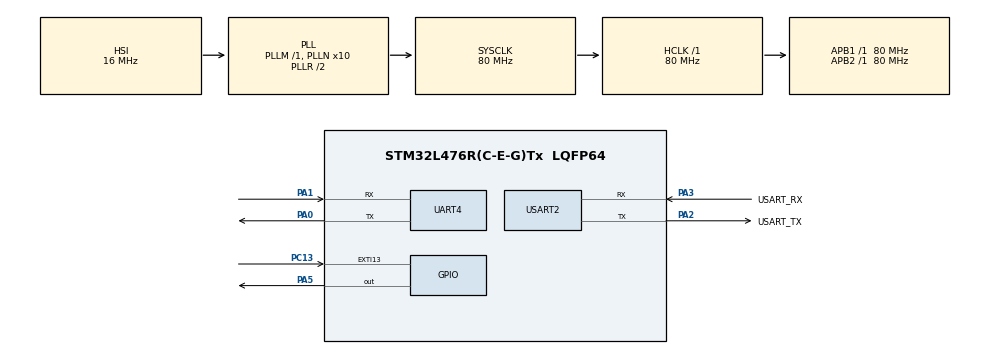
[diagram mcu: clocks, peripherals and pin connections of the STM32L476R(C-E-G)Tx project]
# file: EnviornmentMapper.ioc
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Mcu.Family=STM32L4
Mcu.Name=STM32L476R(C-E-G)Tx
Mcu.Package=LQFP64
NUCLEO-L476RG.BUTTON=1
NUCLEO-L476RG.LD2=true
NVIC.EXTI15_10_IRQn=true\:0\:0\:false\:false\:true\:false\:true\:true
NVIC.PriorityGroup=NVIC_PRIORITYGROUP_4
PA0.Mode=Asynchronous
PA0.Signal=UART4_TX
PA1.Mode=Asynchronous
PA1.Signal=UART4_RX
PA13\ (JTMS-SWDIO).GPIO_Label=TMS
PA13\ (JTMS-SWDIO).Signal=SYS_JTMS-SWDIO
PA14\ (JTCK-SWCLK).GPIO_Label=TCK
PA14\ (JTCK-SWCLK).Signal=SYS_JTCK-SWCLK
PA2.GPIO_Label=USART_TX
PA2.GPIO_Mode=GPIO_MODE_AF_PP
PA2.GPIO_PuPd=GPIO_NOPULL
PA2.GPIO_Speed=GPIO_SPEED_FREQ_VERY_HIGH
PA2.Mode=Asynchronous
PA2.Signal=USART2_TX
PA3.GPIO_Label=USART_RX
PA3.GPIO_Mode=GPIO_MODE_AF_PP
PA3.GPIO_PuPd=GPIO_NOPULL
PA3.GPIO_Speed=GPIO_SPEED_FREQ_VERY_HIGH
PA3.Mode=Asynchronous
PA3.Signal=USART2_RX
PA5.Signal=GPIO_Output
PB3\ (JTDO-TRACESWO).GPIO_Label=SWO
PB3\ (JTDO-TRACESWO).Signal=SYS_JTDO-SWO
PC13.Signal=GPXTI13
PC14-OSC32_IN\ (PC14).Signal=RCC_OSC32_IN
PC15-OSC32_OUT\ (PC15).Signal=RCC_OSC32_OUT
PH0-OSC_IN\ (PH0).Signal=RCC_OSC_IN
PH1-OSC_OUT\ (PH1).Signal=RCC_OSC_OUT
ProjectManager.HeapSize=0x200
ProjectManager.StackSize=0x400
ProjectManager.TargetToolchain=STM32CubeIDE
RCC.ADCFreq_Value=64000000
RCC.AHBFreq_Value=80000000
RCC.APB1Freq_Value=80000000
RCC.APB1TimFreq_Value=80000000
RCC.APB2Freq_Value=80000000
RCC.APB2TimFreq_Value=80000000
RCC.CortexFreq_Value=80000000
RCC.HCLKFreq_Value=80000000
RCC.HSE_VALUE=8000000
RCC.HSI_VALUE=16000000
RCC.LSE_VALUE=32768
RCC.MSI_VALUE=4000000
RCC.PLLN=10
RCC.PLLSourceVirtual=RCC_PLLSOURCE_HSI
RCC.PREFETCH_ENABLE=1
RCC.SYSCLKFreq_VALUE=80000000
RCC.SYSCLKSource=RCC_SYSCLKSOURCE_PLLCLK
RCC.USBFreq_Value=64000000
RCC.VCOOutputFreq_Value=160000000
USART2.VirtualMode-Asynchronous=VM_ASYNC
VP_NUCLEO-L476RG_VS_BSP_COMMON.Mode=COMMON
board=NUCLEO-L476RG

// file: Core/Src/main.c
/* USER CODE BEGIN Header */
/**
  ******************************************************************************
  * @file           : main.c
  * @brief          : Main program body
  ******************************************************************************
  * @attention
  *
  * Copyright (c) 2026 STMicroelectronics.
  * All rights reserved.
  *
  * This software is licensed under terms that can be found in the LICENSE file
  * in the root directory of this software component.
  * If no LICENSE file comes with this software, it is provided AS-IS.
  *
  ******************************************************************************
  */
/* USER CODE END Header */
#include "main.h"
#include "stdio.h"

UART_HandleTypeDef huart4;
UART_HandleTypeDef huart2;

/* USER CODE BEGIN PV */
// Buffer for UART transmission/reception

uint8_t obuffer[8]; // onput buffer (this really is the input buffer, but I didn't want to change it since obuffer looks cooler than ibuffer)
int pan_amt;
int tilt_amt;
int distance;

/* USER CODE END PV */

void SystemClock_Config(void);
static void MX_GPIO_Init(void);
static void MX_UART4_Init(void);
static void MX_USART2_UART_Init(void);
/* USER CODE BEGIN PFP */
#define PUTCHAR_PROTOTYPE int __io_putchar(int ch)
/* USER CODE END PFP */

int main(void)
{

  /* MCU Configuration--------------------------------------------------------*/

  /* Reset of all peripherals, Initializes the Flash interface and the Systick. */
  HAL_Init();

  /* Configure the system clock */
  SystemClock_Config();

  /* Initialize all configured peripherals */
  MX_GPIO_Init();
  MX_UART4_Init();
  MX_USART2_UART_Init();

  /* Initialize leds */
  BSP_LED_Init(LED_GREEN);

  /* Initialize USER push-button, will be used to trigger an interrupt each time it's pressed.*/
  BSP_PB_Init(BUTTON_USER, BUTTON_MODE_EXTI);

  /* Infinite loop */
  /* USER CODE BEGIN WHILE */
  while (1)
  {
	pan_amt = 0;
	tilt_amt = 0;
	// Receive data, 0x56, 0x56, distance, distance
	// Which is essentially a state machine
	// Which is irrelevant to the actual program, just the more you know
	/*while (1) {
		HAL_UART_Receive(&huart4, obuffer, 1, 0xFFFF); // State 0
		if (obuffer[0] == 59) { // Cortex M4 does not have speculative execution so this isn't terrible
			// Do it again
			HAL_UART_Receive(&huart4, obuffer, 1, 0xFFFF); // State 1
			if (obuffer[0] == 59) { // Cortex M4 does not have speculative execution so this isn't terrible
						// Now we actually recieve the data
						HAL_UART_Receive(&huart4, obuffer, 1, 0xFFFF);
						distance = obuffer[0];
						HAL_UART_Receive(&huart4, obuffer, 1, 0xFFFF);
						distance = obuffer[0];
						break; // Break from loop to transmit data
					}
		}
	}*/
	// Recieve From UART4 (Pin A1), this only recieves the first bit for some reason,
	// meaning we need to increase the 'obuffer'
	HAL_UART_Receive(&huart4, obuffer, 8, 0xFFFF);
	// Transmit with newline
	// printf("%d%d%d\n\r", pan_amt, tilt_amt, distance);
	printf("%x-%x-%x-%x-%x-%x-%x-%x\n\r", obuffer[0], obuffer[1], obuffer[2], obuffer[3], obuffer[4], obuffer[5], obuffer[6], obuffer[7]);
	// Delay
	HAL_Delay(1000);

    /* USER CODE END WHILE */

  }
}

void SystemClock_Config(void)
{
  RCC_OscInitTypeDef RCC_OscInitStruct = {0};
  RCC_ClkInitTypeDef RCC_ClkInitStruct = {0};

  /** Configure the main internal regulator output voltage
  */
  if (HAL_PWREx_ControlVoltageScaling(PWR_REGULATOR_VOLTAGE_SCALE1) != HAL_OK)
  {
    Error_Handler();
  }

  /** Initializes the RCC Oscillators according to the specified parameters
  * in the RCC_OscInitTypeDef structure.
  */
  RCC_OscInitStruct.OscillatorType = RCC_OSCILLATORTYPE_HSI;
  RCC_OscInitStruct.HSIState = RCC_HSI_ON;
  RCC_OscInitStruct.HSICalibrationValue = RCC_HSICALIBRATION_DEFAULT;
  RCC_OscInitStruct.PLL.PLLState = RCC_PLL_ON;
  RCC_OscInitStruct.PLL.PLLSource = RCC_PLLSOURCE_HSI;
  RCC_OscInitStruct.PLL.PLLM = 1;
  RCC_OscInitStruct.PLL.PLLN = 10;
  RCC_OscInitStruct.PLL.PLLP = RCC_PLLP_DIV7;
  RCC_OscInitStruct.PLL.PLLQ = RCC_PLLQ_DIV2;
  RCC_OscInitStruct.PLL.PLLR = RCC_PLLR_DIV2;
  if (HAL_RCC_OscConfig(&RCC_OscInitStruct) != HAL_OK)
  {
    Error_Handler();
  }

  /** Initializes the CPU, AHB and APB buses clocks
  */
  RCC_ClkInitStruct.ClockType = RCC_CLOCKTYPE_HCLK|RCC_CLOCKTYPE_SYSCLK
                              |RCC_CLOCKTYPE_PCLK1|RCC_CLOCKTYPE_PCLK2;
  RCC_ClkInitStruct.SYSCLKSource = RCC_SYSCLKSOURCE_PLLCLK;
  RCC_ClkInitStruct.AHBCLKDivider = RCC_SYSCLK_DIV1;
  RCC_ClkInitStruct.APB1CLKDivider = RCC_HCLK_DIV1;
  RCC_ClkInitStruct.APB2CLKDivider = RCC_HCLK_DIV1;

  if (HAL_RCC_ClockConfig(&RCC_ClkInitStruct, FLASH_LATENCY_4) != HAL_OK)
  {
    Error_Handler();
  }
}

static void MX_UART4_Init(void)
{

  huart4.Instance = UART4;
  huart4.Init.BaudRate = 115200;
  huart4.Init.WordLength = UART_WORDLENGTH_8B;
  huart4.Init.StopBits = UART_STOPBITS_1;
  huart4.Init.Parity = UART_PARITY_NONE;
  huart4.Init.Mode = UART_MODE_TX_RX;
  huart4.Init.HwFlowCtl = UART_HWCONTROL_NONE;
  huart4.Init.OverSampling = UART_OVERSAMPLING_16;
  huart4.Init.OneBitSampling = UART_ONE_BIT_SAMPLE_DISABLE;
  huart4.AdvancedInit.AdvFeatureInit = UART_ADVFEATURE_NO_INIT;
  if (HAL_UART_Init(&huart4) != HAL_OK)
  {
    Error_Handler();
  }

}

static void MX_USART2_UART_Init(void)
{

  huart2.Instance = USART2;
  huart2.Init.BaudRate = 115200;
  huart2.Init.WordLength = UART_WORDLENGTH_8B;
  huart2.Init.StopBits = UART_STOPBITS_1;
  huart2.Init.Parity = UART_PARITY_NONE;
  huart2.Init.Mode = UART_MODE_TX_RX;
  huart2.Init.HwFlowCtl = UART_HWCONTROL_NONE;
  huart2.Init.OverSampling = UART_OVERSAMPLING_16;
  huart2.Init.OneBitSampling = UART_ONE_BIT_SAMPLE_DISABLE;
  huart2.AdvancedInit.AdvFeatureInit = UART_ADVFEATURE_NO_INIT;
  if (HAL_UART_Init(&huart2) != HAL_OK)
  {
    Error_Handler();
  }

}

static void MX_GPIO_Init(void)
{

  /* GPIO Ports Clock Enable */
  __HAL_RCC_GPIOC_CLK_ENABLE();
  __HAL_RCC_GPIOH_CLK_ENABLE();
  __HAL_RCC_GPIOA_CLK_ENABLE();
  __HAL_RCC_GPIOB_CLK_ENABLE();

}

/* USER CODE BEGIN 4 */
// Code from lab to replace print with uart
PUTCHAR_PROTOTYPE
{
 /* Place your implementation of fputc here */
 /* e.g. write a character to the USART1 and Loop until the end of transmission */
 HAL_UART_Transmit(&huart2, (uint8_t *)&ch, 1, 0xFFFF);
 return ch;
}

/* USER CODE END 4 */

void Error_Handler(void)
{
  __disable_irq();
  while (1)
  {
  }
}
